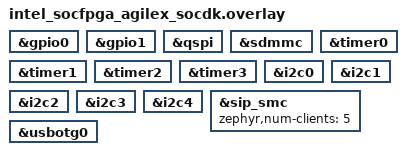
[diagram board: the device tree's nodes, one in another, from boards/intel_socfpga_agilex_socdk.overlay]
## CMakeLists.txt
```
# Copyright (c) 2022-2023, Intel Corporation.
# SPDX-License-Identifier: Apache-2.0

cmake_minimum_required(VERSION 3.20.0)

find_package(Zephyr REQUIRED HINTS $ENV{ZEPHYR_BASE})
project(cli)

target_sources(app PRIVATE src/main.c)
```

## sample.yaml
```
sample:
  name: Agilex general features
tests:
  sample.board.intel_socfpga.cli:
    platform_allow: intel_socfpga
    tags: agilexfpga
```

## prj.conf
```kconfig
# Enable Shell
CONFIG_SHELL=y
CONFIG_SHELL_MINIMAL=y
CONFIG_SHELL_CMD_BUFF_SIZE=4096
CONFIG_SHELL_BACKEND_SERIAL=y
CONFIG_SHELL_HELP=y
CONFIG_SHELL_HISTORY=y
CONFIG_SHELL_HISTORY_BUFFER=1024

# Enable Device Shell to Access Basic Device Data
CONFIG_DEVICE_SHELL=y

#Misc
CONFIG_HEAP_MEM_POOL_SIZE=65536
```

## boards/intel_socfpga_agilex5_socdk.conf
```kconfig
# Copyright (c) 2022-2023, Intel Corporation.
# SPDX-License-Identifier: Apache-2.0

# Misc
CONFIG_SHELL_STACK_SIZE=8192

# Enable QSPI Flash
CONFIG_FLASH=y
CONFIG_FLASH_PAGE_LAYOUT=y
CONFIG_FLASH_SHELL=y

# Setting the Shell prompt
CONFIG_SHELL_PROMPT_UART="agilex5$ "

# Setting the max argc
CONFIG_SHELL_ARGC_MAX=12

# Enable timer driver
CONFIG_COUNTER=y

# Enable Timer shell commands
CONFIG_COUNTER_SHELL=y

# DMA driver
CONFIG_DMA=y
CONFIG_DMA_DW_AXI_MAX_DESC=50

# PSCI shell Enable
CONFIG_PSCI_SHELL=y

#SiP SVC Service
CONFIG_ARM_SIP_SVC_DRIVER=y
CONFIG_ARM_SIP_SVC_SUBSYS=y
CONFIG_ARM_SIP_SVC_SUBSYS_SINGLY_OPEN=y

#SiP SVC Service Shell
CONFIG_ARM_SIP_SVC_SUBSYS_SHELL=y
# GPIO
CONFIG_GPIO=y
CONFIG_GPIO_SHELL=y
CONFIG_GPIO_SHELL_INFO_CMD=n

# Watchdog
CONFIG_WATCHDOG=y
CONFIG_WDT_SHELL=y
```

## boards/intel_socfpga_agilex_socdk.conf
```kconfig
# Copyright (c) 2021-2023, Intel Corporation.
# SPDX-License-Identifier: Apache-2.0

# FPGA Bridge
CONFIG_FPGA_BRIDGE=y
CONFIG_FPGA_BRIDGE_INTEL=y
CONFIG_FPGA_BRIDGE_SHELL=y

# FPGA Manager
CONFIG_FPGA_MANAGER=y
CONFIG_FPGA_MANAGER_SHELL=y
CONFIG_FPGA_MANAGER_INTEL=y

# Misc
CONFIG_HEAP_MEM_POOL_SIZE=16384
CONFIG_SHELL_STACK_SIZE=5120

# Enable QSPI Flash
CONFIG_FLASH=y
CONFIG_FLASH_PAGE_LAYOUT=y

# Setting the Shell prompt
CONFIG_SHELL_PROMPT_UART="agilex$ "

# Configure print buffer size
CONFIG_SHELL_PRINTF_BUFF_SIZE=128

# Enable File System Shell
CONFIG_FILE_SYSTEM_SHELL=y

# Enable timer driver
CONFIG_COUNTER=y

# Enable Timer shell commands
CONFIG_COUNTER_SHELL=y

# Enable I2C Console
CONFIG_I2C=y
CONFIG_I2C_SHELL=y
CONFIG_I2C_SMBUS_SUPPORTED=n

# GPIO Controller
CONFIG_GPIO=y
CONFIG_GPIO_INTEL_SOCFPGA=y
CONFIG_GPIO_SHELL=y

# Enable Disk access
CONFIG_DISK_ACCESS=y

# Enable SDMMC
CONFIG_DISK_DRIVERS=y
CONFIG_DISK_DRIVER_SDMMC=y

# File System Setting
CONFIG_FILE_SYSTEM=y
CONFIG_FAT_FILESYSTEM_ELM=y

# Enable SDHC
CONFIG_SDHC=y

# PSCI support Enable
CONFIG_PM_CPU_OPS=y
CONFIG_PM_CPU_OPS_PSCI=y

#SiP SVC Service
CONFIG_ARM_SIP_SVC_DRIVER=y
CONFIG_ARM_SIP_SVC_SUBSYS=y
CONFIG_ARM_SIP_SVC_SUBSYS_SINGLY_OPEN=y

#SiP SVC Service Shell
CONFIG_ARM_SIP_SVC_SUBSYS_SHELL=y

# Enable USB DWC2 Host stack
CONFIG_USB_HOST_CLASS_DRIVER=y
CONFIG_USB_HOST_MSC_DRIVER=y
CONFIG_DISK_DRIVER_USB2=y
CONFIG_USBH_SHELL=n
```

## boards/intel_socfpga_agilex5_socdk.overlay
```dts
/*
 * Copyright (C) 2023 Intel Corporation
 * SPDX-License-Identifier: Apache-2.0
 */

/* The overlay file should be used to enable any
 * dts nodes required by this application for this
 * board.
 */

&timer0 {
	status = "okay";
};

&timer1 {
	status = "okay";
};

&timer2 {
	status = "okay";
};

&timer3 {
	status = "okay";
};

&dma0 {
	status = "okay";
};

&dma1 {
	status = "okay";
};

&sip_smc {
	status = "okay";
	zephyr,num-clients = <5>;
};

&gpio0 {
	status = "okay";
};

&gpio1 {
	status = "okay";
};

&watchdog0 {
	interrupt-parent = <&gic>;
	interrupts = <GIC_SPI 117 IRQ_TYPE_LEVEL
		      IRQ_DEFAULT_PRIORITY>;
	status = "okay";
};
```

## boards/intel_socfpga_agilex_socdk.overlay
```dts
/*
 * Copyright (C) 2023 Intel Corporation
 * SPDX-License-Identifier: Apache-2.0
 */

/* The overlay file should be used to enable any
 * dts nodes required by this application for this
 * board.
 */

&gpio0 {
	status = "okay";
};

&gpio1 {
	status = "okay";
};

&qspi {
	status = "okay";
};

&sdmmc {
	status = "okay";
};

&timer0 {
	status = "okay";
};

&timer1 {
	status = "okay";
};

&timer2 {
	status = "okay";
};

&timer3 {
	status = "okay";
};

&i2c0 {
	status = "okay";
};

&i2c1 {
	status = "okay";
};

&i2c2 {
	status = "okay";
};

&i2c3 {
	status = "okay";
};

&i2c4 {
	status = "okay";
};

&sip_smc {
	status = "okay";
	zephyr,num-clients = <5>;
};

&usbotg0 {
	status = "okay";
};
```

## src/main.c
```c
/*
 * Copyright (c) 2022-2023, Intel Corporation.
 *
 * SPDX-License-Identifier: Apache-2.0
 */

#include <zephyr/kernel.h>
#include <zephyr/sys/printk.h>

int main(void)
{
	printk("%s: Starting Command Line Interface...\n", CONFIG_BOARD);
}
```
